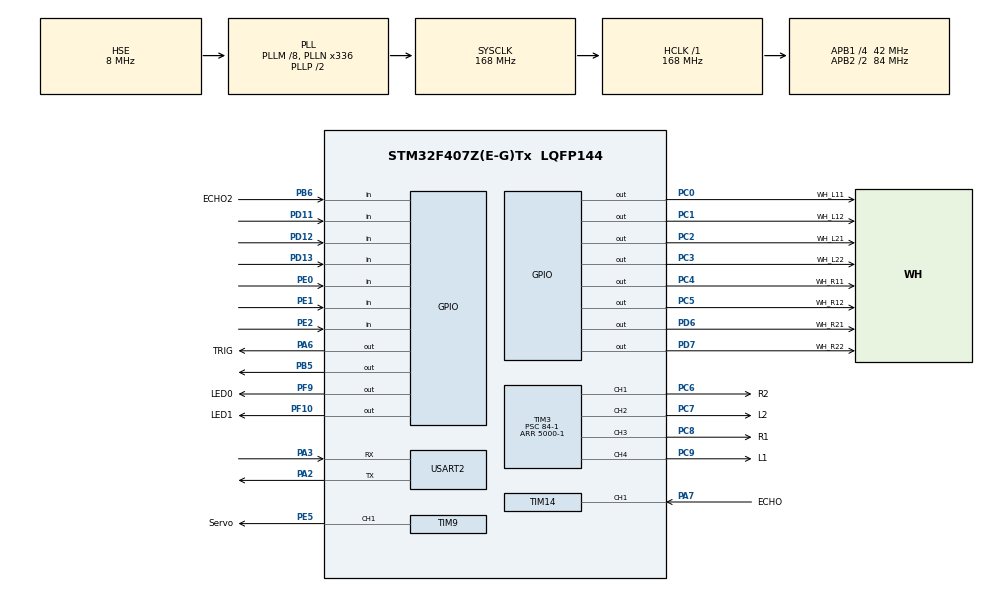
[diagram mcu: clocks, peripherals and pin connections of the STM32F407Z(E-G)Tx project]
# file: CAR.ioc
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Mcu.Family=STM32F4
Mcu.Name=STM32F407Z(E-G)Tx
Mcu.Package=LQFP144
NVIC.PriorityGroup=NVIC_PRIORITYGROUP_4
NVIC.TIM2_IRQn=true\:0\:0\:true\:false\:true\:true\:true
NVIC.TIM8_TRG_COM_TIM14_IRQn=true\:2\:0\:true\:false\:true\:true\:true
NVIC.USART2_IRQn=true\:2\:0\:true\:false\:true\:true\:true
PA2.Mode=Asynchronous
PA2.Signal=USART2_TX
PA3.Mode=Asynchronous
PA3.Signal=USART2_RX
PA6.GPIO_Label=TRIG
PA6.GPIO_PuPd=GPIO_PULLDOWN
PA6.GPIO_Speed=GPIO_SPEED_FREQ_VERY_HIGH
PA6.PinState=GPIO_PIN_SET
PA6.Signal=GPIO_Output
PA7.GPIO_Label=ECHO
PA7.GPIO_PuPd=GPIO_PULLDOWN
PA7.GPIO_Speed=GPIO_SPEED_FREQ_VERY_HIGH
PA7.Signal=S_TIM14_CH1
PB5.GPIO_PuPd=GPIO_PULLDOWN
PB5.GPIO_Speed=GPIO_SPEED_FREQ_HIGH
PB5.PinState=GPIO_PIN_SET
PB5.Signal=GPIO_Output
PB6.GPIO_Label=ECHO2
PB6.GPIO_PuPd=GPIO_NOPULL
PB6.Signal=GPIO_Input
PC0.GPIO_Label=WH_L11
PC0.GPIO_PuPd=GPIO_PULLDOWN
PC0.GPIO_Speed=GPIO_SPEED_FREQ_HIGH
PC0.PinState=GPIO_PIN_SET
PC0.Signal=GPIO_Output
PC1.GPIO_Label=WH_L12
PC1.GPIO_PuPd=GPIO_PULLDOWN
PC1.GPIO_Speed=GPIO_SPEED_FREQ_HIGH
PC1.PinState=GPIO_PIN_SET
PC1.Signal=GPIO_Output
PC2.GPIO_Label=WH_L21
PC2.GPIO_PuPd=GPIO_PULLDOWN
PC2.GPIO_Speed=GPIO_SPEED_FREQ_HIGH
PC2.PinState=GPIO_PIN_SET
PC2.Signal=GPIO_Output
PC3.GPIO_Label=WH_L22
PC3.GPIO_PuPd=GPIO_PULLDOWN
PC3.GPIO_Speed=GPIO_SPEED_FREQ_HIGH
PC3.PinState=GPIO_PIN_SET
PC3.Signal=GPIO_Output
PC4.GPIO_Label=WH_R11
PC4.GPIO_PuPd=GPIO_PULLDOWN
PC4.GPIO_Speed=GPIO_SPEED_FREQ_HIGH
PC4.PinState=GPIO_PIN_SET
PC4.Signal=GPIO_Output
PC5.GPIO_Label=WH_R12
PC5.GPIO_PuPd=GPIO_PULLDOWN
PC5.GPIO_Speed=GPIO_SPEED_FREQ_HIGH
PC5.PinState=GPIO_PIN_SET
PC5.Signal=GPIO_Output
PC6.GPIO_Label=R2
PC6.GPIO_PuPd=GPIO_PULLUP
PC6.GPIO_Speed=GPIO_SPEED_FREQ_HIGH
PC6.Signal=S_TIM3_CH1
PC7.GPIO_Label=L2
PC7.GPIO_PuPd=GPIO_PULLUP
PC7.GPIO_Speed=GPIO_SPEED_FREQ_HIGH
PC7.Signal=S_TIM3_CH2
PC8.GPIO_Label=R1
PC8.GPIO_PuPd=GPIO_PULLUP
PC8.GPIO_Speed=GPIO_SPEED_FREQ_HIGH
PC8.Signal=S_TIM3_CH3
PC9.GPIO_Label=L1
PC9.GPIO_PuPd=GPIO_PULLUP
PC9.GPIO_Speed=GPIO_SPEED_FREQ_HIGH
PC9.Signal=S_TIM3_CH4
PD11.GPIO_PuPd=GPIO_PULLUP
PD11.Signal=GPIO_Input
PD12.GPIO_PuPd=GPIO_PULLUP
PD12.Signal=GPIO_Input
PD13.GPIO_PuPd=GPIO_PULLUP
PD13.Signal=GPIO_Input
PD6.GPIO_Label=WH_R21
PD6.GPIO_PuPd=GPIO_PULLDOWN
PD6.GPIO_Speed=GPIO_SPEED_FREQ_HIGH
PD6.PinState=GPIO_PIN_SET
PD6.Signal=GPIO_Output
PD7.GPIO_Label=WH_R22
PD7.GPIO_PuPd=GPIO_PULLDOWN
PD7.GPIO_Speed=GPIO_SPEED_FREQ_HIGH
PD7.PinState=GPIO_PIN_SET
PD7.Signal=GPIO_Output
PE0.GPIO_PuPd=GPIO_PULLDOWN
PE0.Signal=GPIO_Input
PE1.GPIO_PuPd=GPIO_PULLDOWN
PE1.Signal=GPIO_Input
PE2.GPIO_PuPd=GPIO_PULLDOWN
PE2.Signal=GPIO_Input
PE5.GPIO_Label=Servo
PE5.GPIO_PuPd=GPIO_PULLDOWN
PE5.GPIO_Speed=GPIO_SPEED_FREQ_HIGH
PE5.Signal=S_TIM9_CH1
PF10.GPIO_Label=LED1
PF10.GPIO_PuPd=GPIO_PULLUP
PF10.GPIO_Speed=GPIO_SPEED_FREQ_HIGH
PF10.Signal=GPIO_Output
PF9.GPIO_Label=LED0
PF9.GPIO_PuPd=GPIO_PULLUP
PF9.GPIO_Speed=GPIO_SPEED_FREQ_HIGH
PF9.Signal=GPIO_Output
PH0-OSC_IN.Mode=HSE-External-Oscillator
PH0-OSC_IN.Signal=RCC_OSC_IN
PH1-OSC_OUT.Mode=HSE-External-Oscillator
PH1-OSC_OUT.Signal=RCC_OSC_OUT
ProjectManager.HeapSize=0x200
ProjectManager.StackSize=0x400
ProjectManager.TargetToolchain=MDK-ARM V5
RCC.48MHZClocksFreq_Value=84000000
RCC.AHBFreq_Value=168000000
RCC.APB1CLKDivider=RCC_HCLK_DIV4
RCC.APB1Freq_Value=42000000
RCC.APB1TimFreq_Value=84000000
RCC.APB2CLKDivider=RCC_HCLK_DIV2
RCC.APB2Freq_Value=84000000
RCC.APB2TimFreq_Value=168000000
RCC.CortexFreq_Value=168000000
RCC.HCLKFreq_Value=168000000
RCC.HSE_VALUE=8000000
RCC.HSI_VALUE=16000000
RCC.LSE_VALUE=32768
RCC.PLLM=8
RCC.PLLN=336
RCC.PLLSourceVirtual=RCC_PLLSOURCE_HSE
RCC.SYSCLKFreq_VALUE=168000000
RCC.SYSCLKSource=RCC_SYSCLKSOURCE_PLLCLK
RCC.VCOOutputFreq_Value=336000000
SH.S_TIM14_CH1.0=TIM14_CH1,Input_Capture1_from_TI1
SH.S_TIM3_CH1.0=TIM3_CH1,PWM Generation1 CH1
SH.S_TIM3_CH2.0=TIM3_CH2,PWM Generation2 CH2
SH.S_TIM3_CH3.0=TIM3_CH3,PWM Generation3 CH3
SH.S_TIM3_CH4.0=TIM3_CH4,PWM Generation4 CH4
SH.S_TIM9_CH1.0=TIM9_CH1,PWM Generation1 CH1
TIM14.Channel=TIM_CHANNEL_1
TIM14.Period=65536-1
TIM14.Prescaler=84-1
TIM2.Period=1000000-1
TIM2.Prescaler=84-1
TIM2.TIM_MasterOutputTrigger=TIM_TRGO_RESET
TIM3.Channel-PWM\ Generation1\ CH1=TIM_CHANNEL_1
TIM3.Channel-PWM\ Generation2\ CH2=TIM_CHANNEL_2
TIM3.Channel-PWM\ Generation3\ CH3=TIM_CHANNEL_3
TIM3.Channel-PWM\ Generation4\ CH4=TIM_CHANNEL_4
TIM3.Period=5000-1
TIM3.Prescaler=84-1
TIM3.Pulse-PWM\ Generation1\ CH1=1000
TIM3.Pulse-PWM\ Generation2\ CH2=1000
TIM3.Pulse-PWM\ Generation3\ CH3=1000
TIM3.Pulse-PWM\ Generation4\ CH4=1000
TIM6.Period=65535
TIM6.Prescaler=83
TIM7.Period=65535
TIM7.Prescaler=83
TIM9.Channel-PWM\ Generation1\ CH1=TIM_CHANNEL_1
TIM9.Period=20000-1
TIM9.Prescaler=168-1
USART2.VirtualMode=VM_ASYNC
VP_TIM14_VS_ClockSourceINT.Mode=Enable_Timer
VP_TIM2_VS_ClockSourceINT.Mode=Internal
VP_TIM3_VS_ClockSourceINT.Mode=Internal
VP_TIM6_VS_ClockSourceINT.Mode=Enable_Timer
VP_TIM7_VS_ClockSourceINT.Mode=Enable_Timer
VP_TIM9_VS_ClockSourceINT.Mode=Internal
board=CAR

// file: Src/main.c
/**
  ******************************************************************************
  * File Name          : main.c
  * Description        : Main program body
  ******************************************************************************
  *
  * COPYRIGHT(c) 2020 STMicroelectronics
  *
  * Redistribution and use in source and binary forms, with or without modification,
  * are permitted provided that the following conditions are met:
  *   1. Redistributions of source code must retain the above copyright notice,
  *      this list of conditions and the following disclaimer.
  *   2. Redistributions in binary form must reproduce the above copyright notice,
  *      this list of conditions and the following disclaimer in the documentation
  *      and/or other materials provided with the distribution.
  *   3. Neither the name of STMicroelectronics nor the names of its contributors
  *      may be used to endorse or promote products derived from this software
  *      without specific prior written permission.
  *
  * THIS SOFTWARE IS PROVIDED BY THE COPYRIGHT HOLDERS AND CONTRIBUTORS "AS IS"
  * AND ANY EXPRESS OR IMPLIED WARRANTIES, INCLUDING, BUT NOT LIMITED TO, THE
  * IMPLIED WARRANTIES OF MERCHANTABILITY AND FITNESS FOR A PARTICULAR PURPOSE ARE
  * DISCLAIMED. IN NO EVENT SHALL THE COPYRIGHT HOLDER OR CONTRIBUTORS BE LIABLE
  * FOR ANY DIRECT, INDIRECT, INCIDENTAL, SPECIAL, EXEMPLARY, OR CONSEQUENTIAL
  * DAMAGES (INCLUDING, BUT NOT LIMITED TO, PROCUREMENT OF SUBSTITUTE GOODS OR
  * SERVICES; LOSS OF USE, DATA, OR PROFITS; OR BUSINESS INTERRUPTION) HOWEVER
  * CAUSED AND ON ANY THEORY OF LIABILITY, WHETHER IN CONTRACT, STRICT LIABILITY,
  * OR TORT (INCLUDING NEGLIGENCE OR OTHERWISE) ARISING IN ANY WAY OUT OF THE USE
  * OF THIS SOFTWARE, EVEN IF ADVISED OF THE POSSIBILITY OF SUCH DAMAGE.
  *
  ******************************************************************************
  */
#include "stm32f4xx_hal.h"
#include "tim.h"
#include "usart.h"
#include "gpio.h"

/* USER CODE BEGIN Includes */
#include "motor.h"
#include "elude.h"
#include "track.h"
#include "usmart.h"
#include "stm32f4xx_it.h"
#include "hc05.h"
#include "servo.h"
#include "z_usart.h"
#include "hcsr04.h"
#include "ultrasonic.h"
#include "my_delay.h"
/* USER CODE END Includes */

/* USER CODE BEGIN PV */
/* Private variables ---------------------------------------------------------*/

/* USER CODE END PV */

void SystemClock_Config(void);

/* USER CODE BEGIN PFP */
/* Private function prototypes -----------------------------------------------*/

/* USER CODE END PFP */

int main(void)
{

  /* MCU Configuration----------------------------------------------------------*/

  /* Reset of all peripherals, Initializes the Flash interface and the Systick. */
  HAL_Init();

  /* Configure the system clock */
  SystemClock_Config();

  /* Initialize all configured peripherals */
  MX_GPIO_Init();
  SystemClock_Config();
  MX_TIM2_Init();
  MX_TIM3_Init();
  MX_TIM9_Init();
  MX_TIM14_Init();
  MX_USART2_UART_Init();
  MX_TIM6_Init();
  MX_TIM7_Init();

  /* USER CODE BEGIN 2 */

//Angle_control(0);
   // HAL_GPIO_WritePin(GPIOF,GPIO_PIN_10,GPIO_PIN_SET);

  /* USER CODE END 2 */

  /* Infinite loop */
  /* USER CODE BEGIN WHILE */
//  while (1)
// {
  /* USER CODE END WHILE */
	Ultrasonic_Eluge();

  /* USER CODE BEGIN 3 */
//
// }
  /* USER CODE END 3 */

}

/** System Clock Configuration
*/
void SystemClock_Config(void)
{

  RCC_OscInitTypeDef RCC_OscInitStruct;
  RCC_ClkInitTypeDef RCC_ClkInitStruct;

  __HAL_RCC_PWR_CLK_ENABLE();

  __HAL_PWR_VOLTAGESCALING_CONFIG(PWR_REGULATOR_VOLTAGE_SCALE1);

  RCC_OscInitStruct.OscillatorType = RCC_OSCILLATORTYPE_HSE;
  RCC_OscInitStruct.HSEState = RCC_HSE_ON;
  RCC_OscInitStruct.PLL.PLLState = RCC_PLL_ON;
  RCC_OscInitStruct.PLL.PLLSource = RCC_PLLSOURCE_HSE;
  RCC_OscInitStruct.PLL.PLLM = 8;
  RCC_OscInitStruct.PLL.PLLN = 336;
  RCC_OscInitStruct.PLL.PLLP = RCC_PLLP_DIV2;
  RCC_OscInitStruct.PLL.PLLQ = 4;
  HAL_RCC_OscConfig(&RCC_OscInitStruct);

  RCC_ClkInitStruct.ClockType = RCC_CLOCKTYPE_HCLK|RCC_CLOCKTYPE_SYSCLK
                              |RCC_CLOCKTYPE_PCLK1|RCC_CLOCKTYPE_PCLK2;
  RCC_ClkInitStruct.SYSCLKSource = RCC_SYSCLKSOURCE_PLLCLK;
  RCC_ClkInitStruct.AHBCLKDivider = RCC_SYSCLK_DIV1;
  RCC_ClkInitStruct.APB1CLKDivider = RCC_HCLK_DIV4;
  RCC_ClkInitStruct.APB2CLKDivider = RCC_HCLK_DIV2;
  HAL_RCC_ClockConfig(&RCC_ClkInitStruct, FLASH_LATENCY_5);

  HAL_SYSTICK_Config(HAL_RCC_GetHCLKFreq()/1000);

  HAL_SYSTICK_CLKSourceConfig(SYSTICK_CLKSOURCE_HCLK);

  /* SysTick_IRQn interrupt configuration */
  HAL_NVIC_SetPriority(SysTick_IRQn, 0, 0);
}

/************************ (C) COPYRIGHT STMicroelectronics *****END OF FILE****/
